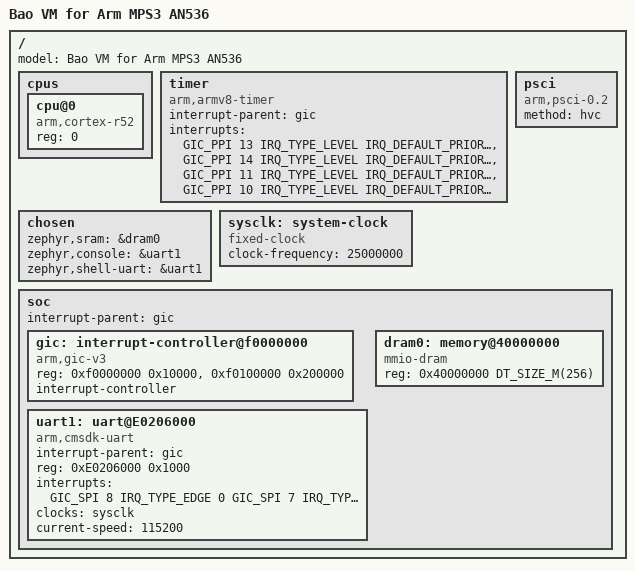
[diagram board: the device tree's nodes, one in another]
/*
 * Copyright (c) 2021 Arm Limited (or its affiliates). All rights reserved.
 * SPDX-License-Identifier: Apache-2.0
 */

#include <mem.h>
#include <zephyr/dt-bindings/interrupt-controller/arm-gic.h>

/dts-v1/;

/ {
	model = "Bao VM for Arm MPS3 AN536";
    #address-cells = <1>;
    #size-cells = <1>;

	cpus {
		#address-cells = <1>;
		#size-cells = <0>;

		cpu@0 {
			device_type = "cpu";
			compatible = "arm,cortex-r52";
			reg = <0>;
		};
	};

	timer {
		compatible = "arm,armv8-timer";
		interrupt-parent = <&gic>;
		interrupts = <GIC_PPI 13 IRQ_TYPE_LEVEL
			      IRQ_DEFAULT_PRIORITY>,
			     <GIC_PPI 14 IRQ_TYPE_LEVEL
			      IRQ_DEFAULT_PRIORITY>,
			     <GIC_PPI 11 IRQ_TYPE_LEVEL
			      IRQ_DEFAULT_PRIORITY>,
			     <GIC_PPI 10 IRQ_TYPE_LEVEL
			      IRQ_DEFAULT_PRIORITY>;
	};

	chosen {
		/*
		 * The SRAM node is actually located in the
		 * DRAM region of the FVP BaseR AEMv8R.
		 */
		zephyr,sram = &dram0;
		zephyr,console = &uart1;
		zephyr,shell-uart = &uart1;
	};

	psci {
		compatible = "arm,psci-0.2";
		method = "hvc";
	};

    sysclk: system-clock {
        compatible = "fixed-clock";
        clock-frequency = <25000000>;
        #clock-cells = <0>;
    };

	soc {
		interrupt-parent = <&gic>;
		#address-cells = <1>;
		#size-cells = <1>;

		gic: interrupt-controller@f0000000 {
            #address-cells = <0>;
			compatible = "arm,gic-v3", "arm,gic";
			reg = <0xf0000000 0x10000>,
			      <0xf0100000 0x200000>;
			interrupt-controller;
			#interrupt-cells = <4>;
			status = "okay";
		};

        uart1: uart@E0206000 {
            interrupt-parent = <&gic>;
            compatible = "arm,cmsdk-uart";
            reg = <0xE0206000 0x1000>;
            interrupts = <
                GIC_SPI 8 IRQ_TYPE_EDGE 0
                GIC_SPI 7 IRQ_TYPE_EDGE 0
            >;
            interrupt-names = "tx", "rx";
            clocks = <&sysclk>;
            current-speed = <115200>;
			status = "okay";
        };

		dram0: memory@40000000 {
			compatible = "mmio-dram";
			reg = <0x40000000 DT_SIZE_M(256)>;
		};
	};
};
